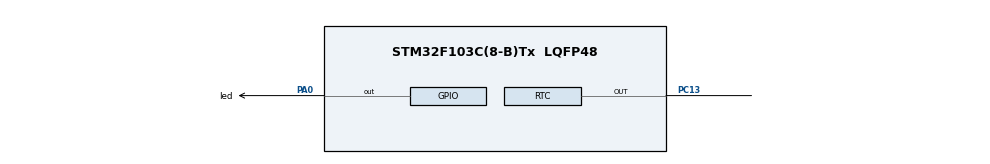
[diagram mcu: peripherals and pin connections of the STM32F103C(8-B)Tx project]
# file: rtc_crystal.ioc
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Mcu.Family=STM32F1
Mcu.Name=STM32F103C(8-B)Tx
Mcu.Package=LQFP48
NVIC.PriorityGroup=NVIC_PRIORITYGROUP_4
PA0-WKUP.GPIO_Label=led
PA0-WKUP.Signal=GPIO_Output
PC13-TAMPER-RTC.Mode=RTC OUT
PC13-TAMPER-RTC.Signal=RTC_OUT
PC14-OSC32_IN.Mode=LSE-External-Oscillator
PC14-OSC32_IN.Signal=RCC_OSC32_IN
PC15-OSC32_OUT.Mode=LSE-External-Oscillator
PC15-OSC32_OUT.Signal=RCC_OSC32_OUT
ProjectManager.HeapSize=0x200
ProjectManager.StackSize=0x400
ProjectManager.TargetToolchain=STM32CubeIDE
RCC.APB1Freq_Value=8000000
RCC.APB2Freq_Value=8000000
RCC.RTCClockSelection=RCC_RTCCLKSOURCE_LSE
VP_RTC_VS_RTC_Activate.Mode=RTC_Enabled
board=custom

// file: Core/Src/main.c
/* USER CODE BEGIN Header */
/**
  ******************************************************************************
  * @file           : main.c
  * @brief          : Main program body
  ******************************************************************************
  * @attention
  *
  * Copyright (c) 2023 STMicroelectronics.
  * All rights reserved.
  *
  * This software is licensed under terms that can be found in the LICENSE file
  * in the root directory of this software component.
  * If no LICENSE file comes with this software, it is provided AS-IS.
  *
  ******************************************************************************
  */
/* USER CODE END Header */
#include "main.h"

RTC_HandleTypeDef hrtc;

/* USER CODE BEGIN PV */
RTC_DateTypeDef data;
RTC_TimeTypeDef tempo;

uint8_t min = 0;
uint8_t seg = 0;
uint8_t seg_antigo = 13;

/* USER CODE END PV */

void SystemClock_Config(void);
static void MX_GPIO_Init(void);
static void MX_RTC_Init(void);

int main(void)
{

  /* MCU Configuration--------------------------------------------------------*/

  /* Reset of all peripherals, Initializes the Flash interface and the Systick. */
  HAL_Init();

  /* Configure the system clock */
  SystemClock_Config();

  /* Initialize all configured peripherals */
  MX_GPIO_Init();
  MX_RTC_Init();
  /* USER CODE BEGIN 2 */
  tempo.Seconds = 30;
  tempo.Minutes = 13;
  HAL_RTC_SetTime(&hrtc, &tempo, FORMAT_BIN);

  /* USER CODE END 2 */

  /* Infinite loop */
  /* USER CODE BEGIN WHILE */
  while (1)
  {
	  HAL_RTC_GetDate(&hrtc, &data, FORMAT_BIN);
	  HAL_RTC_GetTime(&hrtc, &tempo, FORMAT_BIN);

	  seg = tempo.Seconds;
	  min = tempo.Minutes;

	  if(seg!= seg_antigo){
		  HAL_GPIO_TogglePin(GPIOA,led_Pin);
	  }

	  seg_antigo= seg;
    /* USER CODE END WHILE */

  }
}

void SystemClock_Config(void)
{
  RCC_OscInitTypeDef RCC_OscInitStruct = {0};
  RCC_ClkInitTypeDef RCC_ClkInitStruct = {0};
  RCC_PeriphCLKInitTypeDef PeriphClkInit = {0};

  /** Initializes the RCC Oscillators according to the specified parameters
  * in the RCC_OscInitTypeDef structure.
  */
  RCC_OscInitStruct.OscillatorType = RCC_OSCILLATORTYPE_HSI|RCC_OSCILLATORTYPE_LSE;
  RCC_OscInitStruct.LSEState = RCC_LSE_ON;
  RCC_OscInitStruct.HSIState = RCC_HSI_ON;
  RCC_OscInitStruct.HSICalibrationValue = RCC_HSICALIBRATION_DEFAULT;
  RCC_OscInitStruct.PLL.PLLState = RCC_PLL_NONE;
  if (HAL_RCC_OscConfig(&RCC_OscInitStruct) != HAL_OK)
  {
    Error_Handler();
  }

  /** Initializes the CPU, AHB and APB buses clocks
  */
  RCC_ClkInitStruct.ClockType = RCC_CLOCKTYPE_HCLK|RCC_CLOCKTYPE_SYSCLK
                              |RCC_CLOCKTYPE_PCLK1|RCC_CLOCKTYPE_PCLK2;
  RCC_ClkInitStruct.SYSCLKSource = RCC_SYSCLKSOURCE_HSI;
  RCC_ClkInitStruct.AHBCLKDivider = RCC_SYSCLK_DIV1;
  RCC_ClkInitStruct.APB1CLKDivider = RCC_HCLK_DIV1;
  RCC_ClkInitStruct.APB2CLKDivider = RCC_HCLK_DIV1;

  if (HAL_RCC_ClockConfig(&RCC_ClkInitStruct, FLASH_LATENCY_0) != HAL_OK)
  {
    Error_Handler();
  }
  PeriphClkInit.PeriphClockSelection = RCC_PERIPHCLK_RTC;
  PeriphClkInit.RTCClockSelection = RCC_RTCCLKSOURCE_LSE;
  if (HAL_RCCEx_PeriphCLKConfig(&PeriphClkInit) != HAL_OK)
  {
    Error_Handler();
  }
}

static void MX_RTC_Init(void)
{

  RTC_TimeTypeDef sTime = {0};
  RTC_DateTypeDef DateToUpdate = {0};
  RTC_AlarmTypeDef sAlarm = {0};

  /** Initialize RTC Only
  */
  hrtc.Instance = RTC;
  hrtc.Init.AsynchPrediv = RTC_AUTO_1_SECOND;
  hrtc.Init.OutPut = RTC_OUTPUTSOURCE_ALARM;
  if (HAL_RTC_Init(&hrtc) != HAL_OK)
  {
    Error_Handler();
  }

  /** Initialize RTC and set the Time and Date
  */
  sTime.Hours = 0x0;
  sTime.Minutes = 0x0;
  sTime.Seconds = 0x0;

  if (HAL_RTC_SetTime(&hrtc, &sTime, RTC_FORMAT_BCD) != HAL_OK)
  {
    Error_Handler();
  }
  DateToUpdate.WeekDay = RTC_WEEKDAY_MONDAY;
  DateToUpdate.Month = RTC_MONTH_JANUARY;
  DateToUpdate.Date = 0x1;
  DateToUpdate.Year = 0x0;

  if (HAL_RTC_SetDate(&hrtc, &DateToUpdate, RTC_FORMAT_BCD) != HAL_OK)
  {
    Error_Handler();
  }

  /** Enable the Alarm A
  */
  sAlarm.AlarmTime.Hours = 0x0;
  sAlarm.AlarmTime.Minutes = 0x0;
  sAlarm.AlarmTime.Seconds = 0x0;
  sAlarm.Alarm = RTC_ALARM_A;
  if (HAL_RTC_SetAlarm(&hrtc, &sAlarm, RTC_FORMAT_BCD) != HAL_OK)
  {
    Error_Handler();
  }

}

static void MX_GPIO_Init(void)
{
  GPIO_InitTypeDef GPIO_InitStruct = {0};

  /* GPIO Ports Clock Enable */
  __HAL_RCC_GPIOC_CLK_ENABLE();
  __HAL_RCC_GPIOA_CLK_ENABLE();

  /*Configure GPIO pin Output Level */
  HAL_GPIO_WritePin(led_GPIO_Port, led_Pin, GPIO_PIN_RESET);

  /*Configure GPIO pin : led_Pin */
  GPIO_InitStruct.Pin = led_Pin;
  GPIO_InitStruct.Mode = GPIO_MODE_OUTPUT_PP;
  GPIO_InitStruct.Pull = GPIO_NOPULL;
  GPIO_InitStruct.Speed = GPIO_SPEED_FREQ_LOW;
  HAL_GPIO_Init(led_GPIO_Port, &GPIO_InitStruct);

}

void Error_Handler(void)
{
  __disable_irq();
  while (1)
  {
  }
}
